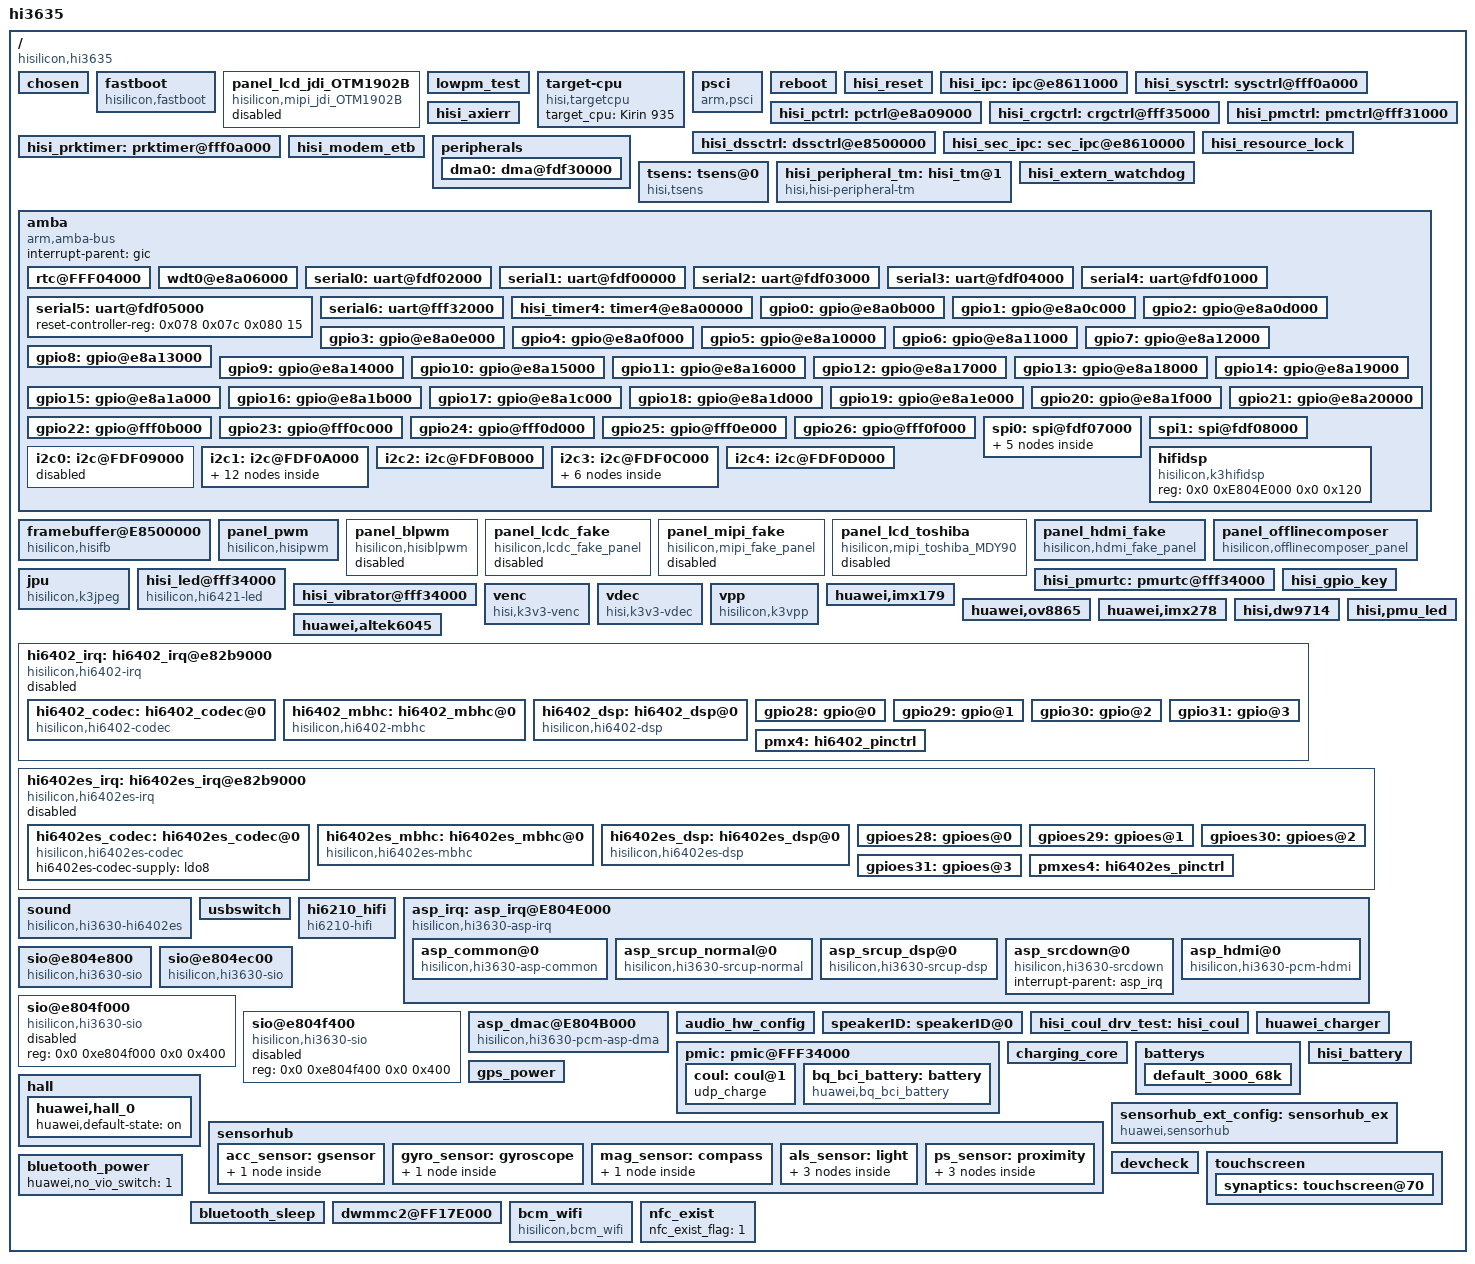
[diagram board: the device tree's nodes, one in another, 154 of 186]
/**
 * Huawei Ltd.
 * PhosphorV660
 */

/dts-v1/;
/{
	#address-cells = <2>;
	#size-cells = <2>;
	model = "hi3635";
	compatible = "hisilicon,hi3635";
	interrupt-parent = <&gic>;

	hisi,boardid = <1 0 0 1>;
	hisi,boardname = "hi3635_asic";

	chosen{};

	fastboot {
		compatible = "hisilicon,fastboot";
		gpio-keyup = <203>;
		gpio-keydown = <204>;
	};

	panel_lcd_jdi_OTM1902B {
		#address-cells = <2>;
		#size-cells = <2>;
		compatible = "hisilicon,mipi_jdi_OTM1902B";
		gpios = <&gpio4 3 0>, <&gpio4 5 0>, <&gpio4 6 0>, <&gpio5 1 0>, <&gpio5 2 0>;
		lcdio-vcc-supply = <&lsw50>;
		lcdanalog-vcc-supply = <&ldo17>;
		pinctrl-names = "default", "idle";
		pinctrl-0 = <&gpio036_pmx_func &gpio035_cfg_func &gpio036_cfg_func &gpio037_cfg_func &gpio038_cfg_func &gpio041_cfg_func &gpio042_cfg_func>;
		pinctrl-1 = <&gpio036_pmx_idle &gpio035_cfg_idle &gpio036_cfg_idle &gpio037_cfg_idle &gpio038_cfg_idle &gpio041_cfg_idle &gpio042_cfg_idle>;
		status = "disabled";
	};

};

/include/ "hi3635_asic_modem_pin.dtsi"
/include/ "hisi_3635.dtsi"
/include/ "hi3635_asic_pin.dtsi"
///include/ "hi3635_asic_charger.dtsi"
///include/ "hi3635_asic_pmic.dtsi"
///include/ "hi3635_asic_gpio_logic.dtsi"
/include/ "hi3635_mmc.dtsi"
/include/ "hi3635_camera.dtsi"
/include/ "./hi3635_udp/hisi_3635_camera3.dtsi"
/include/ "hi3635_ipc.dtsi"
/include/ "hi3635_ddr.dtsi"
/include/ "hisi_6402_codec.dtsi"
/include/ "hisi_6402es_codec.dtsi"
/include/ "hi3635_asic_hi6402_pin.dtsi"

/include/ "hi3635_usb.dtsi"
/include/ "hi3635_efuse.dtsi"
/include/ "huawei_usbswitch.dtsi"

/include/ "hi3635_gpu.dtsi"
/include/ "hi3635_noc.dtsi"
/include/ "hi3635_jpeg.dtsi"
/include/ "hi3635_ion.dtsi"
/include/ "hi3635_pmu.dtsi"
/include/ "hi3635_venc.dtsi"
/include/ "hi3635_vdec.dtsi"
/include/ "hi3635_vpp.dtsi"
/include/ "hisi_sim_hotplug.dtsi"
/include/ "huawei_wifi.dtsi"
/include/ "huawei_bluetooth.dtsi"
/include/ "huawei_gps.dtsi"
/include/ "huawei-sensor.dtsi"
/include/ "bq_bci_battery.dtsi"
/include/ "huawei_charger.dtsi"
/include/ "hisi_battery.dtsi"
/include/ "batterys.dtsi"
/include/ "hisi_coul_drv_test.dtsi"
/include/ "huawei_touchscreen.dtsi"
/include/ "huawei_hall_inputhub.dtsi"
/include/ "huawei_devdetect.dtsi"
/include/ "huawei_nfc.dtsi"
/include/ "huawei_smartpa.dtsi"
/include/ "huawei_audio.dtsi"
/ {
	#address-cells = <2>;
	#size-cells = <2>;

	lowpm_test {
		status = "ok";
	};

	target-cpu {
		compatible = "hisi,targetcpu";
		target_cpu = "Kirin 935";
	};
	psci {
		compatible      = "arm,psci";
		method          = "smc";
		cpu_suspend     = <0xc4000001>;
		cpu_off         = <0x84000002>;
		cpu_on          = <0xc4000003>;
		system_off      = <0x84000008>;
		system_reset    = <0x84000009>;
	};

	reboot {
		status = "ok";
	};

	hisi_reset {
		status = "ok";
	};

	hisi_ipc: ipc@e8611000 {
		status = "ok";
	};

	hisi_sysctrl: sysctrl@fff0a000 {
		status = "ok";
	};

	hisi_pctrl: pctrl@e8a09000 {
		status = "ok";
	};

	hisi_crgctrl: crgctrl@fff35000 {
		status = "ok";
	};

	hisi_dssctrl: dssctrl@e8500000 {
		status = "ok";
	};

	hisi_pmctrl: pmctrl@fff31000 {
		status = "ok";
	};

	hisi_sec_ipc: sec_ipc@e8610000 {
		status = "ok";
	};

	hisi_prktimer: prktimer@fff0a000 {
		status = "ok";
	};

	hisi_resource_lock {
		status = "ok";
	};

	hisi_axierr {
		status = "ok";
	};

	hisi_modem_etb {
		status = "ok";
	};

	peripherals {
		dma0: dma@fdf30000 {
			status = "ok";
		};
	};

	tsens: tsens@0{
		compatible = "hisi,tsens";
		hisi,sensors = <5>;
		hisi,tsensor_enable_cmd = <0x000E000B>;
		hisi,tsensor_disable_cmd = <0x000E010B>;
		hisi,tsensor_read_thermal_h_cmd = <0x000E0208>;
		hisi,tsensor_read_thermal_l_cmd = <0x000E0209>;
		hisi,tsensor_write_thermal_h_cmd = <0x000E0308>;
		hisi,tsensor_write_thermal_l_cmd = <0x000E0309>;
		hisi,tsensor_read_temperature_cmd = <0x000E020B>;
		hisi,tsensor_int_reback_cmd = <0x080E030B>;
	};

	hisi_peripheral_tm: hisi_tm@1 {
		compatible = "hisi,hisi-peripheral-tm";
		hisi,peripheral_sensors = <13>;

		hisi,detect_system_h_tm_chanel = <3>;
		hisi,detect_system_h_tm_ntc = "hi3630_volt_to_temp_general1";
		hisi,detect_system_h_tm_state = "enable";

		hisi,detect_sim_tm_chanel = <5>;
		hisi,detect_sim_tm_ntc = "hi3630_volt_to_temp_general1";
		hisi,detect_sim_tm_state = "disable";

		hisi,detect_system_l_tm_chanel = <6>;
		hisi,detect_system_l_tm_ntc = "hi3630_volt_to_temp_general1";
		hisi,detect_system_l_tm_state = "disable";

		hisi,detect_flash_led_tm_chanel = <9>;
		hisi,detect_flash_led_tm_ntc = "hi3630_volt_to_temp_general1";
		hisi,detect_flash_led_tm_state = "enable";

		hisi,detect_charger_tm_chanel = <12>;
		hisi,detect_charger_tm_ntc = "hi3630_volt_to_temp_general1";
		hisi,detect_charger_tm_state = "enable";

		hisi,detect_pa_0_tm_chanel = <11>;
		hisi,detect_pa_0_tm_ntc = "hi3630_volt_to_temp_general1";
		hisi,detect_pa_0_tm_state = "enable";

		hisi,detect_pa_1_tm_chanel = <13>;
		hisi,detect_pa_1_tm_ntc = "hi3630_volt_to_temp_general1";
		hisi,detect_pa_1_tm_state = "disable";

		hisi,detect_dcxo0_tm_chanel = <10>;
		hisi,detect_dcxo0_tm_ntc = "hi3630_volt_to_temp_general1";
		hisi,detect_dcxo0_tm_state = "disable";

		hisi,detect_dcxo1_tm_chanel = <12>;
		hisi,detect_dcxo1_tm_ntc = "hi3630_volt_to_temp_general1";
		hisi,detect_dcxo1_tm_state = "disable";

		hisi,detect_board0_tm_chanel = <14>;
		hisi,detect_board0_tm_ntc = "hi3630_volt_to_temp_general1";
		hisi,detect_board0_tm_state = "disable";

		hisi,detect_board1_tm_chanel = <15>;
		hisi,detect_board1_tm_ntc = "hi3630_volt_to_temp_general1";
		hisi,detect_board1_tm_state = "disable";

		hisi,detect_board2_tm_chanel = <16>;
		hisi,detect_board2_tm_ntc = "hi3630_volt_to_temp_general1";
		hisi,detect_board2_tm_state = "disable";

		hisi,detect_board3_tm_chanel = <17>;
		hisi,detect_board3_tm_ntc = "hi3630_volt_to_temp_general1";
		hisi,detect_board3_tm_state = "disable";
	};

	hisi_extern_watchdog {
		status = "ok";
	};

	amba {
		#address-cells = <1>;
		#size-cells = <1>;
		compatible = "arm,amba-bus";
		interrupt-parent = <&gic>;
		ranges;

		rtc@FFF04000 {
			status = "ok";
		};

		wdt0@e8a06000 {
			status = "ok";
		};

		serial0: uart@fdf02000 {
			pinctrl-names;
			pinctrl-0;
			pinctrl-1;
			status = "ok";
		};

		serial1: uart@fdf00000 {
			status = "ok";
		};

		serial2: uart@fdf03000 {
			status = "ok";

		};

		serial3: uart@fdf04000 {
			status = "ok";
		};

		serial4: uart@fdf01000 {
			status = "ok";
		};

		serial5: uart@fdf05000 {
			reset-controller-reg = <0x078 0x07c 0x080 15>;
			status = "ok";
		};

		serial6: uart@fff32000 {
			status = "ok";
		};

		hisi_timer4: timer4@e8a00000 {
			status = "ok";
		};

		gpio0: gpio@e8a0b000 {
			status = "ok";
		};

		gpio1: gpio@e8a0c000 {
			status = "ok";
		};

		gpio2: gpio@e8a0d000 {
			status = "ok";
		};

		gpio3: gpio@e8a0e000 {
			status = "ok";
		};

		gpio4: gpio@e8a0f000 {
			status = "ok";
		};

		gpio5: gpio@e8a10000 {
			status = "ok";
		};

		gpio6: gpio@e8a11000 {
			status = "ok";
		};

		gpio7: gpio@e8a12000 {
			status = "ok";
		};

		gpio8: gpio@e8a13000 {
			status = "ok";
		};

		gpio9: gpio@e8a14000 {
			status = "ok";
		};

		gpio10: gpio@e8a15000 {
			status = "ok";
		};

		gpio11: gpio@e8a16000 {
			status = "ok";
		};

		gpio12: gpio@e8a17000 {
			status = "ok";
		};

		gpio13: gpio@e8a18000 {
			status = "ok";
		};

		gpio14: gpio@e8a19000 {
			status = "ok";
		};

		gpio15: gpio@e8a1a000 {
			status = "ok";
		};

		gpio16: gpio@e8a1b000 {
			status = "ok";
		};

		gpio17: gpio@e8a1c000 {
			status = "ok";
		};

		gpio18: gpio@e8a1d000 {
			status = "ok";
		};

		gpio19: gpio@e8a1e000 {
			status = "ok";
		};

		gpio20: gpio@e8a1f000 {
			status = "ok";
		};

		gpio21: gpio@e8a20000 {
			status = "ok";
		};

		gpio22: gpio@fff0b000 {
			status = "ok";
		};

		gpio23: gpio@fff0c000 {
			status = "ok";
		};

		gpio24: gpio@fff0d000 {
			status = "ok";
		};

		gpio25: gpio@fff0e000 {
			status = "ok";
		};

		gpio26: gpio@fff0f000 {
			status = "ok";
		};

		spi0: spi@fdf07000 {
			status = "ok";
			num-cs = <4>;
			pinctrl-names = "default", "idle";
			pinctrl-0 = <&gpio063_pmx_func &gpio065_pmx_func &gpio066_pmx_func &gpio067_pmx_func
					 &gpio068_pmx_func &gpio069_pmx_func &gpio063_cfg_func &gpio064_cfg_func
					 &gpio065_cfg_func &gpio066_cfg_func &gpio067_cfg_func &gpio068_cfg_func
					 &gpio069_cfg_func>;
			pinctrl-1 = <&gpio063_pmx_idle &gpio065_pmx_idle &gpio066_pmx_idle &gpio067_pmx_idle
					 &gpio068_pmx_idle &gpio069_pmx_idle &gpio063_cfg_idle &gpio064_cfg_idle
					 &gpio065_cfg_idle &gpio066_cfg_idle &gpio067_cfg_idle &gpio068_cfg_idle
					 &gpio069_cfg_idle>;
			#address-cells = <1>;
			#size-cells = <0>;
			//cs-gpios = <&gpio9 7 0>, <&gpio10 0 0>, <&gpio10 1 0>, <&gpio10 2 0>;

			/*spi_dev0: spi_dev0@0 {
				compatible = "spi_dev0";
				fpga_flag = <0>;
				spi-max-frequency = <100000>;
				reg = <0>;
				pl022,com-mode = <0>;
				pl022,interface = <0>;
				pl022,rx-level-trig = <3>;
				pl022,tx-level-trig = <3>;
				pl022,ctrl-len = <7>;
				pl022,wait-state = <0>;
				pl022,duplex = <0>;
				pl022,slave-tx-disable = <0>;
			};*/

			mini_isp: mini_isp@0 {
				compatible = "mini_isp";
				spi-max-frequency = <26000000>;
				reg = <0>;
				pl022,com-mode = <2>;
				pl022,interface = <0>;
				pl022,rx-level-trig = <3>;
				pl022,tx-level-trig = <3>;
				pl022,ctrl-len = <7>;
				pl022,wait-state = <0>;
				pl022,duplex = <0>;
				pl022,slave-tx-disable = <0>;

				mini_isp,reset_gpio = <23>;				
				mini_isp,cs_gpio = <66>;
				mini_isp,irq_gpio = <201>;
				mini_isp,dvdd_gpio = <96>;
				//mini_isp,vcc_gpio = <96>;
				iopw-supply = <&lsw52>;				
				pinctrl-names = "default", "idle";
				pinctrl-0 = <&gpio023_pmx_func &gpio023_cfg_func>;
				pinctrl-1 = <&gpio023_pmx_idle &gpio023_cfg_idle>;
			};

			spi_dev1: spi_dev1@1 {
				compatible = "spi_dev1";
				spi-max-frequency = <100000>;
				reg = <1>;
				pl022,com-mode = <0>;
				pl022,interface = <0>;
				pl022,rx-level-trig = <3>;
				pl022,tx-level-trig = <3>;
				pl022,ctrl-len = <7>;
				pl022,wait-state = <0>;
				pl022,duplex = <0>;
				pl022,slave-tx-disable = <0>;
			};

			spi_dev2: spi_dev2@2 {
				compatible = "spi_dev2";
				spi-max-frequency = <100000>;
				reg = <2>;
				pl022,com-mode = <0>;
				pl022,interface = <0>;
				pl022,rx-level-trig = <3>;
				pl022,tx-level-trig = <3>;
				pl022,ctrl-len = <7>;
				pl022,wait-state = <0>;
				pl022,duplex = <0>;
				pl022,slave-tx-disable = <0>;
			};

			spi_dev3: spi_dev3@3 {
				compatible = "spi_dev3";
				spi-max-frequency = <100000>;
				reg = <3>;
				pl022,com-mode = <0>;
				pl022,interface = <0>;
				pl022,rx-level-trig = <3>;
				pl022,tx-level-trig = <3>;
				pl022,ctrl-len = <7>;
				pl022,wait-state = <0>;
				pl022,duplex = <0>;
				pl022,slave-tx-disable = <0>;
			};
			fpga_spi: fpga_spi@4 {
				compatible = "fpga_spi";
				spi-max-frequency = <0x989680>;
				reg = <4>;
				pl022,com-mode = <2>;
				pl022,interface = <0>;
				pl022,rx-level-trig = <3>;
				pl022,tx-level-trig = <3>;
				pl022,ctrl-len = <7>;
				pl022,wait-state = <0>;
				pl022,duplex = <0>;
				pl022,slave-tx-disable = <0>;
			};
		};

		spi1: spi@fdf08000 {
			status = "ok";
			num-cs = <1>;
			pinctrl-names = "default", "idle";
			pinctrl-0 = <>;
			pinctrl-1 = <>;
			/*
			pinctrl-0 = <&gpio146_pmx_func &gpio147_pmx_func &gpio148_pmx_func &gpio149_pmx_func
				     &gpio146_cfg_func &gpio147_cfg_func &gpio148_cfg_func &gpio149_cfg_func>;
			pinctrl-1 = <&gpio146_pmx_idle &gpio147_pmx_idle &gpio148_pmx_idle &gpio149_pmx_idle
				     &gpio146_cfg_idle &gpio147_cfg_idle &gpio148_cfg_idle &gpio149_cfg_idle>;
			*/
			#address-cells = <1>;
			#size-cells = <0>;
			/*
			spi_dev4: spi_dev4@4 {
				compatible = "spi_dev4";
				spi-max-frequency = <100000>;
				reg = <4>;
				pl022,com-mode = <1>;
				pl022,interface = <0>;
				pl022,rx-level-trig = <3>;
				pl022,tx-level-trig = <3>;
				pl022,ctrl-len = <7>;
				pl022,wait-state = <0>;
				pl022,duplex = <0>;
				pl022,slave-tx-disable = <0>;
			};
			*/
		};

		/* I2C0 ~ I2C4
		Notation for etouchscreen and other devices, that is not defined in I2C DTS node:
		if any I2C adapter is disabled, corresponding I2C ID should decreased one by
		one, for example:
			if only I2C0 is disabled, slave devices on I2C1 should get adapter by ID 0
			if only I2C1 is disabled, slave devices on I2C2 should get adapter by ID 1
			and so on........
		*/
		i2c0: i2c@FDF09000 {
			status = "disabled";
			pinctrl-names = "default", "idle";
			pinctrl-0 = <&gpio047_pmx_func &gpio047_cfg_func &gpio048_cfg_func>;
			pinctrl-1 = <&gpio047_pmx_idle &gpio047_cfg_idle &gpio048_cfg_idle>;
			cs-gpios = <&gpio5 7 0>, <&gpio6 0 0>;
		};

		i2c1: i2c@FDF0A000 {
			status = "ok";
			pinctrl-names = "default", "idle";
			pinctrl-0 = <&gpio049_pmx_func &gpio049_cfg_func &gpio050_cfg_func>;
			pinctrl-1 = <&gpio049_pmx_idle &gpio049_cfg_idle &gpio050_cfg_idle>;
			cs-gpios = <&gpio6 1 0>, <&gpio6 2 0>;
			tsc@1A {
				compatible = "cy,cyttsp4_i2c_adapter";
				reg = <0x1A>;
				/* GPIO 17, high-to-low edge triggered */
				//interrupts = <6 2>;
				/* interrupt-parent = <&gpio2>; */
				cy,adapter_id = "cyttsp4_i2c_adapter";
				cy,power_pin = "8226_l28";

				cy,core {
					cy,name = "cyttsp4_core";
					cy,id = "main_ttsp_core";

					cy,irq_gpio = <&gpio4 2 0>;
					cy,rst_gpio = <&gpio8 5 0>;

					/* Enable cy,max_xfer_len to limit max I2C/SPI transfer length */
					/* cy,max_xfer_len = <0x100>; */

					/* CY_CORE_FLAG_WAKE_ON_GESTURE */
					cy,flags = <0>;
					/* CY_CORE_EWG_TAP_TAP | CY_CORE_EWG_TWO_FINGER_SLIDE */
					cy,easy_wakeup_gesture = <3>;
					cy,btn_keys = <102 /* KEY_HOME */
							139 /* KEY_MENU */
							158 /* KEY_BACK */
							217 /* KEY_SEARCH */
							114 /* KEY_VOLUMEDOWN */
							115 /* KEY_VOLUMEUP */
							212 /* KEY_CAMERA */
							116>; /* KEY_POWER */
					cy,btn_keys-tag = <0>;

					cy,mt {
					cy,name = "cyttsp4_mt";

					cy,inp_dev_name = "cyttsp4_mt";
					/* CY_MT_FLAG_FLIP | CY_MT_FLAG_INV_X | CY_MT_FLAG_INV_Y */
					cy,flags = <0x40>;
					cy,abs =
						/* ABS_MT_POSITION_X, CY_ABS_MIN_X, CY_ABS_MAX_X, 0, 0 */
						<0x35 0 540 0 0
						/* ABS_MT_POSITION_Y, CY_ABS_MIN_Y, CY_ABS_MAX_Y, 0, 0 */
						0x36 0 960 0 0
						/* ABS_MT_PRESSURE, CY_ABS_MIN_P, CY_ABS_MAX_P, 0, 0 */
						0x3a 0 255 0 0
						/* CY_IGNORE_VALUE, CY_ABS_MIN_W, CY_ABS_MAX_W, 0, 0 */
						0xffff 0 255 0 0
						/* ABS_MT_TRACKING_ID, CY_ABS_MIN_T, CY_ABS_MAX_T, 0, 0 */
						0x39 0 15 0 0
						/* ABS_MT_TOUCH_MAJOR, 0, 255, 0, 0 */
						0x30 0 255 0 0
						/* ABS_MT_TOUCH_MINOR, 0, 255, 0, 0 */
						0x31 0 255 0 0
						/* ABS_MT_ORIENTATION, -128, 127, 0, 0 */
						0x34 0xfffffed7 127 0 0>;

					cy,vkeys_x = <540>;
					cy,vkeys_y = <960>;

					cy,virtual_keys = /* KeyCode CenterX CenterY Width Height */
						/* KEY_BACK */
						<158 120 1340 200 100
						/* KEY_HOMEPAGE instead of KEY_HOME(102) */
						172 360 1340 200 100
						/* KEY_MENU */
						139 600 1340 200 100>;
						/* KEY SEARCH */
						/*217 1360 630 160 180>;*/
						};

					cy,btn {
						cy,name = "cyttsp4_btn";

						cy,inp_dev_name = "cyttsp4_btn";
					};

					cy,proximity {
						cy,name = "cyttsp4_proximity";

						cy,inp_dev_name = "cyttsp4_proximity";
						cy,abs =
						/* ABS_DISTANCE, CY_PROXIMITY_MIN_VAL, CY_PROXIMITY_MAX_VAL, 0, 0 */
						<0x19 0 1 0 0>;
					};

					cy,loader {
						cy,name = "cyttsp4_loader";

						cy,firmware_name = "cyttsp4_fw_g750.bin";
					};
				};
			};

			huawei,lm3646@67{
				status = "disabled";
			};

			tps65132_phy: tps65132@3e {
			    compatible = "hisilicon,tps65132_phy";
			    reg = <0x3e>;
			    gpios = <&gpio5 1 0>, <&gpio5 2 0>;
			    status = "ok";
			};
			fairchild_fsa9685: fsa9685@25 {
				 status = "ok";
			};
			bq2419x_charger:charger@6B {
				rilim = <220>;
				adc_channel_iin = <10>;
				status = "ok";
			};
			max98925_smartpa:smartpa@31{
				status = "ok";
			};
			pn547_nfc:nfc@28 {
				clk_status="error";
				status = "ok";
				nfc_nxp_name = "libnfc-nxp.conf";
			};
		};

		i2c2: i2c@FDF0B000 {
			status = "ok";
			pinctrl-names = "default", "idle";
			pinctrl-0 = <&gpio051_pmx_func &gpio051_cfg_func &gpio052_cfg_func>;
			pinctrl-1 = <&gpio051_pmx_idle &gpio051_cfg_idle &gpio052_cfg_idle>;
			cs-gpios = <&gpio6 3 0>, <&gpio6 4 0>;
		};

		i2c3: i2c@FDF0C000 {
			status = "ok";
			pinctrl-names = "default", "idle";
			pinctrl-0 = <&gpio017_pmx_func &gpio018_pmx_func &gpio017_cfg_func &gpio018_cfg_func>;
			pinctrl-1 = <&gpio017_pmx_idle &gpio018_pmx_idle &gpio017_cfg_idle &gpio018_cfg_idle>;
			cs-gpios = <&gpio2 1 0>, <&gpio2 2 0>;

			big-core-mon@40 {
				compatible = "hisilicon,big-core-mon";
				reg = <0x40>;
				status = "ok";
			};
			little-core-mon@41 {
				compatible = "hisilicon,little-core-mon";
				reg = <0x41>;
				status = "ok";
			};
			gpu-mon@42 {
				compatible = "hisilicon,gpu-mon";
				reg = <0x42>;
				status = "ok";
			};
			ddr-mon@44 {
				compatible = "hisilicon,ddr-mon";
				reg = <0x44>;
				status = "ok";
			};
			peri-mon@45 {
				compatible = "hisilicon,peri-mon";
				reg = <0x45>;
				status = "ok";
			};
			battery-mon@46 {
				compatible = "hisilicon,battery-mon";
				reg = <0x46>;
				status = "ok";
			};
		};

		i2c4: i2c@FDF0D000 {
			status = "ok";
			pinctrl-names = "default", "idle";
			pinctrl-0 = <&gpio053_pmx_func &gpio053_cfg_func &gpio054_cfg_func>;
			pinctrl-1 = <&gpio053_pmx_idle &gpio053_cfg_idle &gpio054_cfg_idle>;
			cs-gpios = <&gpio6 5 0>, <&gpio6 6 0>;
		};

		hifidsp {
			compatible = "hisilicon,k3hifidsp";
			reg = <0x0 0xE804E000 0x0 0x120>;
			status = "ok";
		};
	};
	/* end amba */

	/* framebuffer & panel begin */
	framebuffer@E8500000 {
		#address-cells = <2>;
		#size-cells = <2>;
		compatible = "hisilicon,hisifb";
		fpga_flag = <0>;
		fastboot_enable_flag = <0>;
		// dss base, CRGPERI base
		reg = <0 0xE8500000 0 0x80000>, <0 0xFFF35000 0 0x1000>;
		// dss-pdp, dss-sdp, dss-adp, dss-dsi0, dss-dsi1 irq
		interrupts = <0 145 4>, <0 146 4>, <0 147 4>, <0 151 4>, <0 152 4>;
		regulator_dsssubsys-supply = <&dsssubsys>;
		regulator_sdp-supply = <&sdp>;
		regulator_adp-supply = <&adp>;
		clocks = <&aclk_gate_dss>, <&clk_gate_edc0>, <&clk_gate_edc1>, <&clk_gate_ldi0>, <&clk_gate_ldi1>, <&pclk_gate_dss>, <&clk_gate_dphy0>, <&clk_gate_dphy1>;
		clock-names = "aclk_dss", "clk_edc0", "clk_edc1", "clk_ldi0", "clk_ldi1", "pclk_dss", "clk_dphy0", "clk_dphy1";
		status = "ok";
	};

	panel_pwm {
		#address-cells = <2>;
		#size-cells = <2>;
		compatible = "hisilicon,hisipwm";
		reg = <0 0xE8A04000 0 0x1000>;
		clocks = <&clk_gate_pwm>;
		clock-names = "clk_pwm";
		pinctrl-names = "default","idle";
		pinctrl-0 = <&gpio098_pmx_func &gpio098_cfg_func>;
		pinctrl-1 = <&gpio098_pmx_idle &gpio098_cfg_idle>;
		status = "ok";
	};

	panel_blpwm {
		#address-cells = <2>;
		#size-cells = <2>;
		compatible = "hisilicon,hisiblpwm";
		reg = <0 0xE8A05000 0 0x1000>;
		clocks = <&clk_gate_pwm1>;
		clock-names = "clk_pwm1";
		pinctrl-names = "default","idle";
		pinctrl-0 = <&gpio098_pmx_func &gpio098_cfg_func>;
		pinctrl-1 = <&gpio098_pmx_idle &gpio098_cfg_idle>;
		status = "disabled";
	};

	panel_lcdc_fake {
		#address-cells = <2>;
		#size-cells = <2>;
		compatible = "hisilicon,lcdc_fake_panel";
		status = "disabled";
	};

	panel_mipi_fake {
		#address-cells = <2>;
		#size-cells = <2>;
		compatible = "hisilicon,mipi_fake_panel";
		gpios = <&gpio4 3 0>, <&gpio4 5 0>, <&gpio4 6 0>, <&gpio5 1 0>, <&gpio5 2 0>;
		lcdio-vcc-supply = <&lsw50>;
		lcdanalog-vcc-supply = <&ldo17>;
		status = "disabled";
	};

	panel_lcd_toshiba {
		#address-cells = <2>;
		#size-cells = <2>;
		compatible = "hisilicon,mipi_toshiba_MDY90";
		gpios = <&gpio4 5 0>, <&gpio5 1 0>;
		lcdio-vcc-supply = <&lsw50>;
		lcdanalog-vcc-supply = <&ldo17>;
		pinctrl-names = "default", "idle";
		pinctrl-0 = <&gpio037_cfg_func &gpio041_cfg_func>;
		pinctrl-1 = <&gpio037_cfg_idle &gpio041_cfg_idle>;
		status = "disabled";
	};

	panel_hdmi_fake {
		#address-cells = <2>;
		#size-cells = <2>;
		compatible = "hisilicon,hdmi_fake_panel";
		status = "ok";
	};

	panel_offlinecomposer {
		#address-cells = <2>;
		#size-cells = <2>;
		compatible = "hisilicon,offlinecomposer_panel";
		status = "ok";
	};
	/* framebuffer & panel end */

	jpu{
		compatible = "hisilicon,k3jpeg";
		reg = <0x0 0xE8960000 0x0 0x7FFF>;
		interrupts = <0 140 4>;
		//clock
		clocks = <&clk_gate_jpeg>;
		clock-names = "clk_jpeg";
		//these are for ldo resources
		ldo_jpu-supply = <&jpegip>;
		status = "ok";
	};

	hisi_pmurtc: pmurtc@fff34000 {
		status = "ok";
	};

	hisi_led@fff34000 {
		compatible = "hisilicon,hi6421-led";
		reg = <0x0 0xfff34000 0x0 0x1000>;
		hi6421,dr3ctrl = "red";
		hi6421,dr4ctrl = "green";
		hi6421,dr5ctrl = "blue";
		status = "ok";
	};
	hisi_vibrator@fff34000 {
		status = "ok";
	};

	hisi_gpio_key {
		status = "ok";
	};

	venc{
		compatible = "hisi,k3v3-venc";
		reg = <0x0 0xe8900000 0x0 0x10000>;
		interrupts = <0 143 4>;
		clocks = <&clk_gate_venc>;
		clock-names = "clk_venc";
		ldo_venc-supply = <&venc>;
		status = "ok";
	};

	vdec{
		compatible = "hisi,k3v3-vdec";
		reg = <0x0 0xe8910000 0x0 0x10000>;
		interrupts = <0 144 4>;
		clocks = <&clk_gate_vdec>;
		clock-names = "clk_vdec";
		ldo_vdec-supply = <&vdec>;
		status = "ok";
	};

	vpp{
		compatible = "hisilicon,k3vpp";
		reg = <0x0 0xE8968000 0x0 0x1FFF>;
		interrupts = <0 141 4>;
		//clock
		clocks = <&clk_gate_vpp>;
		clock-names = "clk_vpp";
		//these are for ldo resources
		ldo_vpp-supply = <&vppip>;
		status = "ok";
	};

	/* isp & camera sensor & vcm begin */

	/* camera subsystem device */

	/* camera sensor device */
	huawei,imx179 {
		status = "ok";
	};

	huawei,ov8865 {
		status = "ok";
	};

	huawei,imx278 {
		status = "ok";
	};

	/* vcm device */
	hisi,dw9714 {
		status = "ok";
	};

	/* mini isp altek6045&6010 */
	huawei,altek6045 {
		status = "ok";
	};

	/* camera flash device */
	/* pmu led flash */
	hisi,pmu_led {
		status = "ok";
	};
	/* isp & camera sensor & vcm end */

	hi6402_irq: hi6402_irq@e82b9000 {
		compatible = "hisilicon,hi6402-irq";
		hi6402-irq-supply = <&ldo8>;
		hi6402-irq-ldo26-supply = <&ldo26>;
		gpios = <&gpio24 6 0>; /* GPIO_198 */
		pinctrl-names = "default", "idle";
		pinctrl-0 = <&gpio016_cfg_func &gpio016_pmx_func
			     &gpio198_cfg_func>;
		pinctrl-1 = <&gpio016_cfg_idle &gpio016_pmx_idle
			     &gpio198_cfg_idle>;
		status = "disable";
		hi6402_codec: hi6402_codec@0{
			compatible = "hisilicon,hi6402-codec";
			status = "ok";
		};

		hi6402_mbhc: hi6402_mbhc@0{
			compatible = "hisilicon,hi6402-mbhc";
			hisilicon,hs_det = <0>;
			hisilicon,hs_3_pole_min_voltage = <0>;
			hisilicon,hs_3_pole_max_voltage = <8>;
			hisilicon,hs_4_pole_min_voltage = <1350>;
			hisilicon,hs_4_pole_max_voltage = <2565>;
			hisilicon,btn_play_min_voltage = <0>;
			hisilicon,btn_play_max_voltage = <100>;
			hisilicon,btn_volume_up_min_voltage = <130>;
			hisilicon,btn_volume_up_max_voltage = <320>;
			hisilicon,btn_volume_down_min_voltage = <320>;
			hisilicon,btn_volume_down_max_voltage = <700>;
			status = "ok";
		};

		hi6402_dsp: hi6402_dsp@0{
			compatible = "hisilicon,hi6402-dsp";
			status = "ok";
		};

		gpio28: gpio@0{
			status = "ok";
		};

		gpio29: gpio@1{
			status = "ok";
		};

		gpio30: gpio@2{
			status = "ok";
		};

		gpio31: gpio@3{
			status = "ok";
		};

		pmx4: hi6402_pinctrl {
			status = "ok";
		};
	};

        hi6402es_irq: hi6402es_irq@e82b9000 {
                compatible = "hisilicon,hi6402es-irq";
                hi6402es-irq-supply = <&ldo8>;
                gpios = <&gpio24 6 0>; /* GPIO_198 */
                pinctrl-names = "default", "idle";
                pinctrl-0 = <&gpio016_cfg_func &gpio016_pmx_func
                             &gpio198_cfg_func>;
                pinctrl-1 = <&gpio016_cfg_idle &gpio016_pmx_idle
                             &gpio198_cfg_idle>;
                status = "disable";
                hi6402es_codec: hi6402es_codec@0{
                        compatible = "hisilicon,hi6402es-codec";
                        hi6402es-codec-supply = <&ldo8>;
                        status = "ok";
                };

                hi6402es_mbhc: hi6402es_mbhc@0{
                        compatible = "hisilicon,hi6402es-mbhc";
                        hisilicon,hs_det = <0>;
                        hisilicon,hs_3_pole_min_voltage = <0>;
                        hisilicon,hs_3_pole_max_voltage = <8>;
                        hisilicon,hs_4_pole_min_voltage = <1350>;
                        hisilicon,hs_4_pole_max_voltage = <2565>;
                        hisilicon,btn_play_min_voltage = <0>;
                        hisilicon,btn_play_max_voltage = <100>;
                        hisilicon,btn_volume_up_min_voltage = <130>;
                        hisilicon,btn_volume_up_max_voltage = <320>;
                        hisilicon,btn_volume_down_min_voltage = <320>;
                        hisilicon,btn_volume_down_max_voltage = <700>;
                        status = "ok";
                };

                hi6402es_dsp: hi6402es_dsp@0{
                        compatible = "hisilicon,hi6402es-dsp";
                        status = "ok";
                };

		gpioes28: gpioes@0{
			status = "ok";
		};

		gpioes29: gpioes@1{
			status = "ok";
		};

		gpioes30: gpioes@2{
			status = "ok";
		};

		gpioes31: gpioes@3{
			status = "ok";
		};

		pmxes4: hi6402es_pinctrl {
			status = "ok";
		};
        };

	sound {
		compatible = "hisilicon,hi3630-hi6402es";
		status = "ok";
	};

	usbswitch: usbswitch {
		status = "ok";
	};

	hi6210_hifi {
		compatible = "hi6210-hifi";
		status = "ok";
	};

	asp_irq: asp_irq@E804E000{
		compatible = "hisilicon,hi3630-asp-irq";
		reg = <0x0 0xe804e000 0x0 0xa000>;
		#interrupt-cells = <0x2>;
		asp-irq-supply = <&asp>;
		interrupt-controller;
		interrupts = <0x0 0x88 0x4>;
		interrupt-names = "asp_irq";

		asp_common@0 {
			compatible = "hisilicon,hi3630-asp-common";
		};

		asp_srcup_normal@0 {
			compatible = "hisilicon,hi3630-srcup-normal";
			asp-srcup-normal-supply = <&asp>;
			interrupt-parent = <&asp_irq>;
			interrupts = <0x1 0x0>;
			interrupt-names = "asp_srcup_normal";
		};

		asp_srcup_dsp@0 {
			compatible = "hisilicon,hi3630-srcup-dsp";
		};

		asp_srcdown@0 {
			compatible = "hisilicon,hi3630-srcdown";
			interrupt-parent = <&asp_irq>;
		};

		asp_hdmi@0 {
			compatible = "hisilicon,hi3630-pcm-hdmi";
			interrupt-parent = <&asp_irq>;
			interrupts = <0x0 0x0>;
			interrupt-names = "asp_irq_hdmi";
		};
	};

	sio@e804e800 {
		compatible = "hisilicon,hi3630-sio";
		reg = <0x0 0xe804e800 0x0 0x400>;
		sio-audio-supply = <&asp>;
		pinctrl-names = "default", "idle";
		pinctrl-0 = <&gpio183_pmx_func
				    &gpio184_pmx_func
				    &gpio185_pmx_func
				    &gpio186_pmx_func
				    &gpio183_cfg_func
				    &gpio184_cfg_func
				    &gpio185_cfg_func
				     &gpio186_cfg_func>;
		pinctrl-1 = <&gpio183_pmx_idle
				    &gpio184_pmx_idle
				    &gpio185_pmx_idle
				    &gpio186_pmx_idle
				    &gpio183_cfg_idle
				    &gpio184_cfg_idle
				    &gpio185_cfg_idle
				    &gpio186_cfg_idle>;
		status = "ok";
	};

	sio@e804ec00 {
		compatible = "hisilicon,hi3630-sio";
		reg = <0x0 0xe804ec00 0x0 0x400>;
		sio-voice-supply = <&asp>;
		pinctrl-names = "default", "idle";
		pinctrl-0 = <&gpio043_pmx_func
				     &gpio044_pmx_func
				     &gpio045_pmx_func
				     &gpio046_pmx_func
				     &gpio043_cfg_func
				     &gpio044_cfg_func
				     &gpio045_cfg_func
				     &gpio046_cfg_func>;
			pinctrl-1 = <&gpio043_pmx_idle
				     &gpio044_pmx_idle
				     &gpio045_pmx_idle
				     &gpio046_pmx_idle
				     &gpio043_cfg_idle
				     &gpio044_cfg_idle
				     &gpio045_cfg_idle
				     &gpio046_cfg_idle>;
		status = "ok";
	};

	sio@e804f000 {
		compatible = "hisilicon,hi3630-sio";
		reg = <0x0 0xe804f000 0x0 0x400>;
		status = "disabled";
	};

	sio@e804f400 {
		compatible = "hisilicon,hi3630-sio";
		reg = <0x0 0xe804f400 0x0 0x400>;
		status = "disabled";
	};

	asp_dmac@E804B000 {
		compatible = "hisilicon,hi3630-pcm-asp-dma";
		reg = <0x0 0xe804b000 0x0 0x1000>;
		asp-dmac-supply = <&asp>;
		interrupts = <0 212 4>;
		interrupt-names = "asp_dma_irq";
	};

	audio_hw_config {
		product_name = "hi3635";
		cust_name = "audio_custom";
		spk_pa_name = "max98925";
		soc_name = "hi363x";
		codec_name = "hi6402";
		codec_dsp_algo = "maxim|mad";
		modem_sio_master = "true";
		status = "ok";
	};

	speakerID: speakerID@0 {
		status = "ok";
	};

	hisi_coul_drv_test:hisi_coul {
		status = "ok";
	};
	pmic: pmic@FFF34000 {
		coul: coul@1 {
			udp_charge;
		};
		bq_bci_battery:battery {
			compatible = "huawei,bq_bci_battery";
			status = "ok";
		};
	};
	huawei_charger:huawei_charger {
		status = "ok";
	};
	charging_core:charging_core {
		iin_ac = <1200>;
		ichg_ac = <1000>;
		status = "ok";
	};
	batterys:batterys {
		default_3000_68k:default_3000_68k {
			vbat_max = <4100>;
			temp_para =
			"-32767","-10","-1","0","4100","0",
			"-10","0","-1","100","4100","0",
			"0","10","-1","900","4100","3",
			"10","45","-1","-1","4100","3",
			"45","50","900","820","4100","3",
			"50","32767","900","0","4100","0";
		};
	};
	hisi_battery:hisi_battery {
		status = "ok";
	};
	gps_power:gps_power{
		status = "ok";
		broadcom_config,ic_type= "bcm47531";
		broadcom_config,tty_port="ttyAMA3";
		broadcom_config,product="hi3635";
	};

	hall {
		status = "ok";
		huawei,hall_0{
			huawei,default-state = "on";
		};
	};
	sensorhub{
		acc_sensor:gsensor{
			acc1{
				compatible="huawei,Invensense_icm20628";
				bus_number=<0>;
				reg=<0x68>;
				chip_id_register=<0x80>;
				chip_id_value=<0xa2 0x90>;
				file_id=<5>;
				sensor_type="acc";
				sensor-vdd-supply = <&ldo24>;
				axis_map_x=<1>;
				axis_map_y=<0>;
				axis_map_z=<2>;
				negate_x=<0>;
				negate_y=<1>;
				negate_z=<0>;
				offset_x=<0>;
				offset_y=<0>;
				offset_z=<0>;
				poll_interval=<10>;
				gpio_int1=<&gpio25 8 0>;
				status = "ok";
			};
		};


		gyro_sensor:gyroscope{
			gyro1{
				compatible="huawei,Invensense_icm20628";
				bus_number=<0>;
				reg=<0x68>;
				chip_id_register=<0x80>;
				chip_id_value=<0xa2 0x90>;
				file_id=<6>;
				sensor_type="gyro";
				sensor-vdd-supply = <&ldo24>;
				axis_map_x=<1>;
				axis_map_y=<0>;
				axis_map_z=<2>;
				negate_x=<0>;
				negate_y=<1>;
				negate_z=<0>;
				poll_interval=<10>;
				gpio_int1=<&gpio25 8 0>;
				status = "ok";
			};
		};

		mag_sensor:compass{
			mag1{
				file_id=<8>;
				compass_extend_data=<1073741824 0 0 0 1073741824 0 0 0 1073741824>;
				status = "ok";
			};
		};

		als_sensor:light{
			als1{
				file_id=<9>;
				GA1=<3790>;
				GA2=<4250>;
				GA3=<4090>;
				status = "ok";
			};
			als2{
				compatible="huawei,mura-lt_1pa01";
				bus_number=<0>;
				reg=<0x44>;
				chip_id_register=<0x0>;
				chip_id_value=<0xc8 0xc9 0xca 0xcf>;
				file_id=<0xF>;
				sensor_list_info_id=<0x3>;
				sensor_type="als";
				sensor-vdd-supply = <&ldo24>;
				poll_interval=<500>;   //?·?31a???ˉ×?D?ê±??????
				threshold_value=<1>;
				GA1=<4166>; //2￡á§í?1a?ê ￡?3??1a?′
				GA2=<3900>; //2￡á§í?1a?ê
				GA3=<4500>; //2￡á§í?1a?ê
				tp_color =<0>;
				again=<0x15>; //′?ì??¤1asensor?D?·?3oìía1a213￥?μêy
				gpio_int1=<&gpio25 6 0>;
				atime=<3>; //′?ì??¤1asensor?Dé?±¨?·?31aêy?μμ?×a???μêy,oí?áμ?2??êóD1?
				init_time = <150>;   //?·?31a3?ê??ˉê±??
				status = "ok";
			};
			als3{
				compatible="huawei,rohm_rpr0521";
				bus_number=<0>;
				reg=<0x38>;
				chip_id_register=<0x92>;
				chip_id_value=<0xE0>;
				file_id=<0x10>;
				sensor_list_info_id=<0x3>;
				sensor_type="als";
				sensor-vdd-supply = <&ldo24>;
				poll_interval=<500>;   //?·?31a???ˉ×?D?ê±??????
				threshold_value=<1>;
				GA1=<0>; //2￡á§í?1a?ê ￡?3??1a?′
				GA2=<0>; //2￡á§í?1a?ê
				GA3=<0>; //2￡á§í?1a?ê
				tp_color =<0>;
				again=<5>; // ROHM ALS gain value in 42h register
				gpio_int1=<&gpio25 6 0>;
				atime=<0>;
				init_time = <150>;   //?·?31a3?ê??ˉê±??
				als_extend_data = <7768 4388 2627 1971 5066 2315 1106 687 1032 1605 1904 2864>; //ROHM ALS coefficient
				status = "ok";
			};
		};

		ps_sensor:proximity{
			ps1{
				file_id=<9>;
				pwave_value=<90>;
				pwindows_value=<120>;
				threshold_value=<100>;
				poll_interval = <150>;
				status = "ok";
			};
			ps2{
				compatible="huawei,mura-lt_1pa01";
				bus_number=<0>;
				reg=<0x44>;
				chip_id_register=<0x0>;
				chip_id_value=<0xc8 0xc9 0xca 0xcf>;
				file_id=<0xF>;
				sensor_list_info_id=<0x4>;
				sensor_type="ps";
				sensor-vdd-supply = <&ldo24>;
				tp_color =<0>;
				min_proximity_value=<200>;
				pwindows_value=<120>;
				pwave_value=<5>;
				threshold_value=<25>;
				ps_pulse_count=<5>;
				persistent=<0x33>;
				rdata_under_sun=<5500>;
				gpio_int1=<&gpio25 6 0>;
				ptime=<0>; //′?ì??¤1asensor?D?ó?ü1a213￥
				p_on = <0>;   //?ˉ???ú??ê?·?Dèòa1?±??§??
				poll_interval = <300>;
				init_time = <50>;
				status = "ok";
			};
			ps3{
				compatible="huawei,rohm_rpr0521";
				bus_number=<0>;
				reg=<0x38>;
				chip_id_register=<0x92>;
				chip_id_value=<0xE0>;
				file_id=<0x10>;
				sensor_list_info_id=<0x4>;
				sensor_type="ps";
				sensor-vdd-supply = <&ldo24>;
				tp_color =<0>;
				min_proximity_value=<750>;
				pwindows_value=<38>;
				pwave_value=<12>;
				threshold_value=<10>;
				ps_pulse_count=<0>; // ROHM PS_PUSLE in 41h register
				persistent=<1>; // ROHM PS_CONTROL in 43h register
				rdata_under_sun=<5500>;
				gpio_int1=<&gpio25 6 0>;
				ptime=<0xFF>;
				p_on = <2>;   // ROHM LED_CURRENT in 42h register
				poll_interval = <300>;
				init_time = <50>;
				status = "ok";
			};
		};
	};

	sensorhub_ext_config:sensorhub_ex{
		compatible = "huawei,sensorhub";
		akm_need_current = "no";
		invensense_exist = "yes";
		isensor_version = "yes";
		adapt_file_id = <0x07>;
	};

	/*
		device check : the 0 means that it don't need to check;
			the 1 means that it check at board check and running test;
			the 2 means that it check at running test
	*/
	devcheck: devcheck {
		touch_panel = <2>;
		compass = <1>;
		g_sensor = <1>;
		gyroscope = <1>;
		nfc = <1>;
		dc_dc = <1>;
		tps = <1>;
		l_sensor = <2>;
		charge = <1>;
		usb_switch = <1>;
		wifi = <1>;
		bt = <1>;
		gps = <1>;
		gpu = <1>;
		cpu_chip = <0>;
		status = "ok";
	};

	touchscreen {
		product = "mogolia";
		has_virtualkey = <0>;
		synaptics: touchscreen@70 {
			algo_id = <1>;
			irq_config = <0>;
			ic_type = <1>;
			x_max = <1080>;
			y_max = <1920>;
			x_max_mt = <1080>;
			y_max_mt = <1920>;
			/*0 is power supplied by gpio, 1 is supplied by ldo*/
			vci_gpio_type = <0>;
			vci_regulator_type = <1>;
			vddio_gpio_type = <0>;
			vddio_regulator_type = <1>;
			pinctrl-names = "default", "idle";
			pinctrl-0 = <&gpio099_cfg_func &gpio200_cfg_func>;
			pinctrl-1 = <&gpio099_cfg_idle &gpio200_cfg_idle>;
			synaptics-vdd-supply = <&ldo17>;
			synaptics-io-supply = <&lsw50>;
			reset_gpio = <&gpio12 3 0>;
			attn_gpio = <&gpio25 0 0>;
			raw_data_limit = "3200", /*rawdata-max*/
					 "1600", /*rawdata-min*/
					 "15", /*deltadata-max*/
					 "-15", /*deltadata-min*/
					 "390", /*rx-to-rx-diff-max*/
					 "-390", /*rx-to-rx-diff-min*/
					 "390", /*tx-to-tx-diff-max*/
					 "-390";/*tx-to-tx-diff-min*/
		};
	};

	bluetooth_power:bluetooth_power{
		huawei,no_vio_switch = <1>;
		status = "ok";
	};

	bluetooth_sleep:bluetooth_sleep{
		status = "ok";
	};

	dwmmc2@FF17E000 {
		status = "ok";
	};

	bcm_wifi {
		compatible = "hisilicon,bcm_wifi";
		clocks = <&clk_pmu32kb>;
		clock-names = "apb_pclk";
		wlan-on,gpio-enable= <&gpio14 1 0>;
		wlan-irq,gpio-irq = <&gpio26 4 0>;
		wifi_nvram_name = "/vendor/firmware/nvram4334_hw.txt";
		wifi_fw_name = "/vendor/firmware/fw_bcm4334_hw.bin";
		wifi_fw_ap_name = "/vendor/firmware/fw_bcm4334_apsta_hw.bin";
		wifi_fw_test_name = "/vendor/firmware/fw_bcm4334_test_hw_apsta.bin";
		udp_board;
		ic_type= "bcm4334";
		status = "ok";
	};
	nfc_exist {/*mark nfc hardware exist, for mmi used*/
		nfc_exist_flag = "1";
		status = "ok";
	};

};

